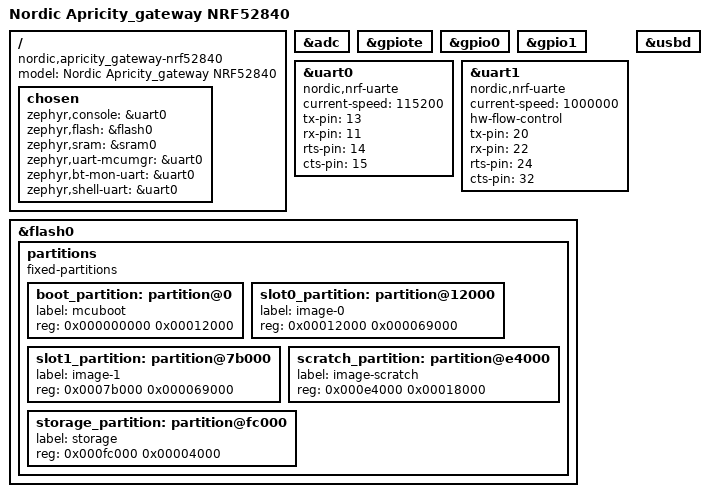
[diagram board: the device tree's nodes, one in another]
/*
 * Copyright (c) 2020 Nordic Semiconductor ASA
 *
 * SPDX-License-Identifier: LicenseRef-BSD-5-Clause-Nordic
 */

/dts-v1/;
#include <nordic/nrf52840_qiaa.dtsi>

/ {
	model = "Nordic Apricity_gateway NRF52840";
	compatible = "nordic,apricity_gateway-nrf52840";

	chosen {
		zephyr,console = &uart0;
		zephyr,flash = &flash0;
		zephyr,sram = &sram0;
		zephyr,uart-mcumgr = &uart0;
		zephyr,bt-mon-uart = &uart0;
		zephyr,shell-uart = &uart0;
	};
};

&adc {
	status = "okay";
};

&gpiote {
	status = "okay";
};

&gpio0 {
	status = "okay";
};

&gpio1 {
	status = "okay";
};

&uart0 {
	compatible = "nordic,nrf-uarte";
	current-speed = <115200>;
	status = "okay";
	tx-pin = < 13 >;
	rx-pin = < 11 >;
	rts-pin = < 14 >;
	cts-pin = < 15 >;
};

&uart1 {
	compatible = "nordic,nrf-uarte";
	current-speed = <1000000>;
	status = "okay";
	hw-flow-control;
	tx-pin = < 20 >;
	rx-pin = < 22 >;
	rts-pin = < 24 >;
	cts-pin = < 32 >;
};

&usbd {
	status = "okay";
};

&flash0 {
	partitions {
		compatible = "fixed-partitions";
		#address-cells = <1>;
		#size-cells = <1>;

		/* The size of this partition ensures that MCUBoot can be built
		 * with an RTT console, CDC ACM support, and w/o optimizations.
		 */
		boot_partition: partition@0 {
			label = "mcuboot";
			reg = <0x000000000 0x00012000>;
		};
		slot0_partition: partition@12000 {
			label = "image-0";
			reg = <0x00012000 0x000069000>;
		};
		slot1_partition: partition@7b000 {
			label = "image-1";
			reg = <0x0007b000 0x000069000>;
		};
		scratch_partition: partition@e4000 {
			label = "image-scratch";
			reg = <0x000e4000 0x00018000>;
		};
		storage_partition: partition@fc000 {
			label = "storage";
			reg = <0x000fc000 0x00004000>;
		};
	};
};
